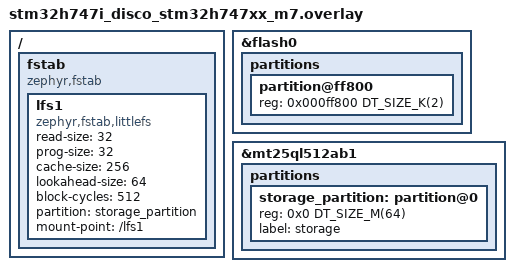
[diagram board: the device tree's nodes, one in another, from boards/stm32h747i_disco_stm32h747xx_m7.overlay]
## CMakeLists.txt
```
# SPDX-License-Identifier: Apache-2.0

cmake_minimum_required(VERSION 3.28.0)
find_package(Zephyr REQUIRED HINTS $ENV{ZEPHYR_BASE})
project(lvgl)

FILE(GLOB app_sources src/*.c)
target_sources(app PRIVATE ${app_sources})
```

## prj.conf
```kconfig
CONFIG_ZTEST=y

CONFIG_DISPLAY=y
CONFIG_SDL_DISPLAY=n

CONFIG_LOG=y

CONFIG_FLASH=y
CONFIG_FLASH_MAP=y
CONFIG_FILE_SYSTEM=y
CONFIG_FILE_SYSTEM_LITTLEFS=y
CONFIG_LV_Z_AUTO_INIT=n

CONFIG_LVGL=y
CONFIG_LV_Z_MEM_POOL_SIZE=16384
CONFIG_LV_Z_USE_FILESYSTEM=y
CONFIG_LV_USE_LOG=y
CONFIG_LV_Z_COLOR_FORMAT_XRGB8888=y
CONFIG_LV_USE_BIDI=y
CONFIG_LV_USE_ARABIC_PERSIAN_CHARS=y
CONFIG_LV_USE_LABEL=y
CONFIG_LV_LABEL_TEXT_SELECTION=y
CONFIG_LV_LABEL_LONG_TXT_HINT=y
CONFIG_LV_USE_LINE=y
CONFIG_LV_USE_ARC=y
CONFIG_LV_USE_WIN=y
CONFIG_LV_USE_TABVIEW=y
CONFIG_LV_USE_TILEVIEW=y
CONFIG_LV_USE_CALENDAR=y
CONFIG_LV_CALENDAR_WEEK_STARTS_MONDAY=y
CONFIG_LV_USE_SPINNER=y
CONFIG_LV_USE_CANVAS=y
CONFIG_LV_USE_BAR=y
CONFIG_LV_USE_CHART=y
CONFIG_LV_USE_TABLE=y
CONFIG_LV_USE_LED=y
CONFIG_LV_USE_MSGBOX=y
CONFIG_LV_USE_TEXTAREA=y
CONFIG_LV_USE_SPINBOX=y
CONFIG_LV_USE_KEYBOARD=y
CONFIG_LV_USE_CHECKBOX=y
CONFIG_LV_USE_LIST=y
CONFIG_LV_USE_DROPDOWN=y
CONFIG_LV_USE_ROLLER=y
CONFIG_LV_USE_SLIDER=y
CONFIG_LV_USE_SWITCH=y
CONFIG_LV_USE_LED=y
CONFIG_LV_FONT_MONTSERRAT_8=y
CONFIG_LV_FONT_MONTSERRAT_10=y
CONFIG_LV_FONT_MONTSERRAT_12=y
CONFIG_LV_FONT_MONTSERRAT_14=y
CONFIG_LV_FONT_MONTSERRAT_16=y
CONFIG_LV_FONT_MONTSERRAT_18=y
CONFIG_LV_FONT_MONTSERRAT_20=y
CONFIG_LV_FONT_MONTSERRAT_22=y
CONFIG_LV_FONT_MONTSERRAT_24=y
CONFIG_LV_FONT_MONTSERRAT_26=y
CONFIG_LV_FONT_MONTSERRAT_28=y
CONFIG_LV_FONT_MONTSERRAT_30=y
CONFIG_LV_FONT_MONTSERRAT_32=y
CONFIG_LV_FONT_MONTSERRAT_34=y
CONFIG_LV_FONT_MONTSERRAT_36=y
CONFIG_LV_FONT_MONTSERRAT_38=y
CONFIG_LV_FONT_MONTSERRAT_40=y
CONFIG_LV_FONT_MONTSERRAT_42=y
CONFIG_LV_FONT_MONTSERRAT_44=y
CONFIG_LV_FONT_MONTSERRAT_46=y
CONFIG_LV_FONT_MONTSERRAT_48=y
CONFIG_LV_FONT_MONTSERRAT_28_COMPRESSED=y
CONFIG_LV_FONT_DEJAVU_16_PERSIAN_HEBREW=y
CONFIG_LV_FONT_SOURCE_HAN_SANS_SC_16_CJK=y
CONFIG_LV_FONT_UNSCII_8=y
CONFIG_LV_USE_FONT_COMPRESSED=y
```

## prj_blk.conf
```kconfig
CONFIG_DISK_DRIVERS=y
CONFIG_DISK_ACCESS=y

CONFIG_FS_LITTLEFS_BLK_DEV=y

CONFIG_FS_LITTLEFS_FC_HEAP_SIZE=2048
CONFIG_MAIN_STACK_SIZE=2048

CONFIG_FLASH=n
CONFIG_FLASH_MAP=n
```

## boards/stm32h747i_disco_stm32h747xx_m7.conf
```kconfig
# SPDX-FileCopyrightText: Copyright The Zephyr Project Contributors
# SPDX-License-Identifier: Apache-2.0

CONFIG_FS_LITTLEFS_FC_HEAP_SIZE=2048
CONFIG_MAIN_STACK_SIZE=2048

CONFIG_DUMMY_DISPLAY=n

CONFIG_NOCACHE_MEMORY=y
```

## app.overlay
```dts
/*
 * Copyright (c) 2021 Nordic Semiconductor ASA
 *
 * SPDX-License-Identifier: Apache-2.0
 */

/ {
	chosen {
		zephyr,display = &dummy_dc;
	};

	dummy_dc: dummy_dc {
		compatible = "zephyr,dummy-dc";
		height = <240>;
		width = <320>;
	};
};
```

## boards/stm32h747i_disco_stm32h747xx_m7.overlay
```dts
/*
 * Copyright (c) 2024 STMicroelectronics
 *
 * SPDX-License-Identifier: Apache-2.0
 */

/delete-node/ &storage_partition;

&flash0 {
	partitions {
		partition@ff800 {
			reg = <0x000ff800 DT_SIZE_K(2)>;
		};
	};
};

/ {
	fstab {
		compatible = "zephyr,fstab";

		lfs1: lfs1 {
			compatible = "zephyr,fstab,littlefs";
			read-size = <32>;
			prog-size = <32>;
			cache-size = <256>;
			lookahead-size = <64>;
			block-cycles = <512>;
			partition = <&storage_partition>;
			mount-point = "/lfs1";
		};
	};
};

&mt25ql512ab1 {
	partitions {
		storage_partition: partition@0 {
			reg = <0x0 DT_SIZE_M(64)>;
			label = "storage";
		};
	};
};
```

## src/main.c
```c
/*
 * Copyright (c) 2019 Jan Van Winkel <jan.van_winkel@dxplore.eu>
 * Copyright (c) 2024 STMicroelectronics
 *
 * SPDX-License-Identifier: Apache-2.0
 */

#include "img.h"

#include <zephyr/kernel.h>
#include <zephyr/device.h>
#include <zephyr/drivers/display.h>
#include <zephyr/fs/fs.h>
#include <zephyr/fs/littlefs.h>
#include <zephyr/ztest.h>
#include <lvgl_zephyr.h>

#include <lvgl.h>

#ifdef CONFIG_FS_LITTLEFS_BLK_DEV

#ifdef CONFIG_DISK_DRIVER_SDMMC
#define DISK_NAME "SD"
#elif defined(CONFIG_DISK_DRIVER_MMC)
#define DISK_NAME "SD2"
#else
#error "No disk device defined, is your board supported?"
#endif /* CONFIG_DISK_DRIVER_SDMMC */

#define IMG_FILE_PATH "/"DISK_NAME":/img.bin"

struct fs_littlefs lfsfs;

static struct fs_mount_t mnt = {
	.type = FS_LITTLEFS,
	.fs_data = &lfsfs,
	.storage_dev = (void *)DISK_NAME,
	.mnt_point = "/"DISK_NAME":",
	.flags = FS_MOUNT_FLAG_USE_DISK_ACCESS,
};

#else /* CONFIG_FS_LITTLEFS_BLK_DEV */

#define IMG_FILE_PATH "/mnt/img.bin"

#define LVGL_PARTITION		storage_partition
#define LVGL_PARTITION_ID	PARTITION_ID(LVGL_PARTITION)

FS_LITTLEFS_DECLARE_DEFAULT_CONFIG(cstorage);

static struct fs_mount_t mnt = {
	.type = FS_LITTLEFS,
	.fs_data = &cstorage,
	.storage_dev = (void *)LVGL_PARTITION_ID,
	.mnt_point = "/mnt"
};
#endif /* CONFIG_FS_LITTLEFS_BLK_DEV */

static const struct device *display_dev = DEVICE_DT_GET(DT_CHOSEN(zephyr_display));

ZTEST(lvgl_screen, test_get_default_screen)
{
	zassert_not_null(lv_scr_act(), "No default screen");
}

ZTEST(lvgl_screen, test_add_delete_screen)
{
	lv_obj_t *default_screen = lv_scr_act();

	zassert_not_null(default_screen, "No default screen");

	lv_obj_t *new_screen = lv_obj_create(NULL);

	zassert_not_null(new_screen, "Failed to create new screen");

	lv_scr_load(new_screen);

	lv_obj_t *act_screen = lv_scr_act();

	zassert_equal_ptr(act_screen, new_screen, "New screen not active");

	lv_scr_load(default_screen);

	lv_obj_del(new_screen);

	act_screen = lv_scr_act();
	zassert_equal_ptr(act_screen, default_screen,
			"Default screen not active");

}
ZTEST_USER(lvgl_fs, test_add_img)
{
	lv_obj_t *img = lv_img_create(lv_scr_act());

	zassert_not_null(img, "Failed to create image");

	lv_img_set_src(img, IMG_FILE_PATH);
	lv_obj_align(img, LV_ALIGN_CENTER, 0, 0);
}

void *setup_lvgl(void)
{
	int ret;

#if defined(CONFIG_LV_COLOR_FORMAT_I1)
	display_set_pixel_format(display_dev, PIXEL_FORMAT_MONO10);
#elif defined(CONFIG_LV_COLOR_FORMAT_L8)
	display_set_pixel_format(display_dev, PIXEL_FORMAT_L_8);
#elif defined(CONFIG_LV_COLOR_FORMAT_RGB888)
	display_set_pixel_format(display_dev, PIXEL_FORMAT_RGB_888);
#elif defined(CONFIG_LV_COLOR_FORMAT_RGB565)
	display_set_pixel_format(display_dev, PIXEL_FORMAT_RGB_565);
#elif defined(CONFIG_LV_COLOR_FORMAT_XRGB8888)
	display_set_pixel_format(display_dev, PIXEL_FORMAT_ARGB_8888);
#else
#error "No display pixel format defined, is your board supported?"
#endif

	ret = lvgl_init();
	zassert_equal(ret, 0, "Failed to initialize lvgl");

	return NULL;
}

void *setup_fs(void)
{
	struct fs_file_t img;
	struct fs_dirent info;
	int ret;
	const lv_image_dsc_t *c_img = get_lvgl_img();

	setup_lvgl();

	ret = fs_mount(&mnt);
	if (ret < 0) {
		TC_PRINT("Failed to mount file system: %d\n", ret);
		ztest_test_fail();
		return NULL;
	}

	ret = fs_stat(IMG_FILE_PATH, &info);
	if ((ret == 0) && (info.type == FS_DIR_ENTRY_FILE)) {
		return NULL;
	}

	fs_file_t_init(&img);
	ret = fs_open(&img, IMG_FILE_PATH, FS_O_CREATE | FS_O_WRITE);
	if (ret < 0) {
		TC_PRINT("Failed to open image file: %d\n", ret);
		ztest_test_fail();
		return NULL;
	}

	ret = fs_write(&img, &c_img->header, sizeof(lv_image_header_t));
	if (ret < 0) {
		TC_PRINT("Failed to write image file header: %d\n", ret);
		ztest_test_fail();
		return NULL;
	}

	ret = fs_write(&img, c_img->data, c_img->data_size);
	if (ret < 0) {
		TC_PRINT("Failed to write image file data: %d\n", ret);
		ztest_test_fail();
		return NULL;
	}

	ret = fs_close(&img);
	if (ret < 0) {
		TC_PRINT("Failed to close image file: %d\n", ret);
		ztest_test_fail();
		return NULL;
	}
	return NULL;
}

void teardown_lvgl(void *data)
{
	lv_deinit();
}

ZTEST(lvgl_mono, test_mono_display)
{
	int ret;

	zassert_ok(display_set_pixel_format(display_dev, PIXEL_FORMAT_MONO10));
	ret = lvgl_init();
	zassert_ok(display_set_pixel_format(display_dev, PIXEL_FORMAT_ARGB_8888));

	if (!IS_ENABLED(CONFIG_LV_COLOR_FORMAT_I1)) {
		zassert_equal(ret, -ENOTSUP, "MONO10 accepted without CONFIG_LV_COLOR_FORMAT_I1");
		return;
	}

	zassert_ok(ret, "MONO10 rejected with CONFIG_LV_COLOR_FORMAT_I1");
	lv_label_set_text(lv_label_create(lv_screen_active()), "mono");
	lv_refr_now(NULL);
}

ZTEST_SUITE(lvgl_screen, NULL, setup_lvgl, NULL, NULL, teardown_lvgl);
ZTEST_SUITE(lvgl_fs, NULL, setup_fs, NULL, NULL, teardown_lvgl);
ZTEST_SUITE(lvgl_mono, NULL, NULL, NULL, NULL, teardown_lvgl);
```

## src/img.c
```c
/*
 * Copyright (c) 2019 Jan Van Winkel <jan.van_winkel@dxplore.eu>
 *
 * SPDX-License-Identifier: Apache-2.0
 */

#include <zephyr/kernel.h>
#include "img.h"

static const uint8_t img_data[] = {
	0x00, 0x00, 0x00, 0x00,	/* Index color 0 */
	0x00, 0xff, 0x00, 0x00,	/* Index color 1 */

/* 0 */
	0xff, 0xff, 0xff, 0xff, 0xff, 0xff, 0xff, 0xff, 0xff, 0xff, 0xff, 0xff,
	0xff, 0xff, 0xff, 0xff, 0xff, 0xff, 0xff, 0xff, 0xff, 0xff, 0xff, 0xff,
	0xff, 0xff, 0xff, 0xff, 0xff, 0xff, 0xff, 0xff, 0xff, 0xff, 0xff, 0xff,
	0xff, 0xff, 0xff, 0xff, 0xff, 0xff, 0xff, 0xff, 0xff, 0xff, 0xff, 0xff,
	0xff, 0xff, 0xff, 0xff, 0xff, 0xff, 0xff, 0xff, 0xff, 0xff, 0xff, 0xff,
	0xff, 0x00, 0x00, 0x00, 0x00, 0x00, 0x00, 0x00, 0x00, 0x00, 0x00, 0xff,
	0xff, 0x00, 0x00, 0x00, 0x00, 0x00, 0x00, 0x00, 0x00, 0x00, 0x00, 0xff,
	0xff, 0x00, 0x00, 0x00, 0x00, 0x00, 0x00, 0x00, 0x00, 0x00, 0x00, 0xff,
	0xff, 0x00, 0x00, 0x00, 0x00, 0x00, 0x00, 0x00, 0x00, 0x00, 0x00, 0xff,
	0xff, 0x00, 0x00, 0x00, 0x00, 0x00, 0x00, 0x00, 0x00, 0x00, 0x00, 0xff,
/* 10 */
	0xff, 0xff, 0xff, 0xff, 0xff, 0xff, 0xff, 0xff, 0xff, 0xff, 0xff, 0xff,
	0xff, 0xff, 0xff, 0xff, 0xff, 0xff, 0xff, 0xff, 0xff, 0xff, 0xff, 0xff,
	0xff, 0xff, 0xff, 0xff, 0xff, 0xff, 0xff, 0xff, 0xff, 0xff, 0xff, 0xff,
	0xff, 0xff, 0xff, 0xff, 0xff, 0xff, 0xff, 0xff, 0xff, 0xff, 0xff, 0xff,
	0xff, 0xff, 0xff, 0xff, 0xff, 0xff, 0xff, 0xff, 0xff, 0xff, 0xff, 0xff,
	0xff, 0x00, 0x00, 0x00, 0x00, 0x00, 0x00, 0x00, 0x00, 0x00, 0x00, 0xff,
	0xff, 0x00, 0x00, 0x00, 0x00, 0x00, 0x00, 0x00, 0x00, 0x00, 0x00, 0xff,
	0xff, 0x00, 0x00, 0x00, 0x00, 0x00, 0x00, 0x00, 0x00, 0x00, 0x00, 0xff,
	0xff, 0x00, 0x00, 0x00, 0x00, 0x00, 0x00, 0x00, 0x00, 0x00, 0x00, 0xff,
	0xff, 0x00, 0x00, 0x00, 0x00, 0x00, 0x00, 0x00, 0x00, 0x00, 0x00, 0xff,
/* 20 */
	0xff, 0xff, 0xff, 0xff, 0xff, 0xff, 0xff, 0xff, 0xff, 0xff, 0xff, 0xff,
	0xff, 0xff, 0xff, 0xff, 0xff, 0xff, 0xff, 0xff, 0xff, 0xff, 0xff, 0xff,
	0xff, 0xff, 0xff, 0xff, 0xff, 0xff, 0xff, 0xff, 0xff, 0xff, 0xff, 0xff,
	0xff, 0xff, 0xff, 0xff, 0xff, 0xff, 0xff, 0xff, 0xff, 0xff, 0xff, 0xff,
	0xff, 0xff, 0xff, 0xff, 0xff, 0xff, 0xff, 0xff, 0xff, 0xff, 0xff, 0xff,
	0xff, 0x00, 0x00, 0x00, 0x00, 0x00, 0x00, 0x00, 0x00, 0x00, 0x00, 0xff,
	0xff, 0x00, 0x00, 0x00, 0x00, 0x00, 0x00, 0x00, 0x00, 0x00, 0x00, 0xff,
	0xff, 0x00, 0x00, 0x00, 0x00, 0x00, 0x00, 0x00, 0x00, 0x00, 0x00, 0xff,
	0xff, 0x00, 0x00, 0x00, 0x00, 0x00, 0x00, 0x00, 0x00, 0x00, 0x00, 0xff,
	0xff, 0x00, 0x00, 0x00, 0x00, 0x00, 0x00, 0x00, 0x00, 0x00, 0x00, 0xff,
/* 30 */
	0xff, 0xff, 0xff, 0xff, 0xff, 0xff, 0xff, 0xff, 0xff, 0xff, 0xff, 0xff,
	0xff, 0xff, 0xff, 0xff, 0xff, 0xff, 0xff, 0xff, 0xff, 0xff, 0xff, 0xff,
	0xff, 0xff, 0xff, 0xff, 0xff, 0xff, 0xff, 0xff, 0xff, 0xff, 0xff, 0xff,
	0xff, 0xff, 0xff, 0xff, 0xff, 0xff, 0xff, 0xff, 0xff, 0xff, 0xff, 0xff,
	0xff, 0xff, 0xff, 0xff, 0xff, 0xff, 0xff, 0xff, 0xff, 0xff, 0xff, 0xff,
	0xff, 0x00, 0x00, 0x00, 0x00, 0x00, 0x00, 0x00, 0x00, 0x00, 0x00, 0xff,
	0xff, 0x00, 0x00, 0x00, 0x00, 0x00, 0x00, 0x00, 0x00, 0x00, 0x00, 0xff,
	0xff, 0x00, 0x00, 0x00, 0x00, 0x00, 0x00, 0x00, 0x00, 0x00, 0x00, 0xff,
	0xff, 0x00, 0x00, 0x00, 0x00, 0x00, 0x00, 0x00, 0x00, 0x00, 0x00, 0xff,
	0xff, 0x00, 0x00, 0x00, 0x00, 0x00, 0x00, 0x00, 0x00, 0x00, 0x00, 0xff,
/* 40 */
	0xff, 0xff, 0xff, 0xff, 0xff, 0xff, 0xff, 0xff, 0xff, 0xff, 0xff, 0xff,
	0xff, 0xff, 0xff, 0xff, 0xff, 0xff, 0xff, 0xff, 0xff, 0xff, 0xff, 0xff,
	0xff, 0xff, 0xff, 0xff, 0xff, 0xff, 0xff, 0xff, 0xff, 0xff, 0xff, 0xff,
	0xff, 0xff, 0xff, 0xff, 0xff, 0xff, 0xff, 0xff, 0xff, 0xff, 0xff, 0xff,
	0xff, 0xff, 0xff, 0xff, 0xff, 0xff, 0xff, 0xff, 0xff, 0xff, 0xff, 0xff,
	0xff, 0x00, 0x00, 0x00, 0x00, 0x00, 0x00, 0x00, 0x00, 0x00, 0x00, 0xff,
	0xff, 0x00, 0x00, 0x00, 0x00, 0x00, 0x00, 0x00, 0x00, 0x00, 0x00, 0xff,
	0xff, 0x00, 0x00, 0x00, 0x00, 0x00, 0x00, 0x00, 0x00, 0x00, 0x00, 0xff,
	0xff, 0x00, 0x00, 0x00, 0x00, 0x00, 0x00, 0x00, 0x00, 0x00, 0x00, 0xff,
	0xff, 0x00, 0x00, 0x00, 0x00, 0x00, 0x00, 0x00, 0x00, 0x00, 0x00, 0xff,
/* 50 */
	0xff, 0xff, 0xff, 0xff, 0xff, 0xff, 0xff, 0xff, 0xff, 0xff, 0xff, 0xff,
	0xff, 0xff, 0xff, 0xff, 0xff, 0xff, 0xff, 0xff, 0xff, 0xff, 0xff, 0xff,
	0xff, 0xff, 0xff, 0xff, 0xff, 0xff, 0xff, 0xff, 0xff, 0xff, 0xff, 0xff,
	0xff, 0xff, 0xff, 0xff, 0xff, 0xff, 0xff, 0xff, 0xff, 0xff, 0xff, 0xff,
	0xff, 0xff, 0xff, 0xff, 0xff, 0xff, 0xff, 0xff, 0xff, 0xff, 0xff, 0xff,
	0xff, 0x00, 0x00, 0x00, 0x00, 0x00, 0x00, 0x00, 0x00, 0x00, 0x00, 0xff,
	0xff, 0x00, 0x00, 0x00, 0x00, 0x00, 0x00, 0x00, 0x00, 0x00, 0x00, 0xff,
	0xff, 0x00, 0x00, 0x00, 0x00, 0x00, 0x00, 0x00, 0x00, 0x00, 0x00, 0xff,
	0xff, 0x00, 0x00, 0x00, 0x00, 0x00, 0x00, 0x00, 0x00, 0x00, 0x00, 0xff,
	0xff, 0x00, 0x00, 0x00, 0x00, 0x00, 0x00, 0x00, 0x00, 0x00, 0x00, 0xff,
/* 60 */
	0xff, 0xff, 0xff, 0xff, 0xff, 0xff, 0xff, 0xff, 0xff, 0xff, 0xff, 0xff,
	0xff, 0xff, 0xff, 0xff, 0xff, 0xff, 0xff, 0xff, 0xff, 0xff, 0xff, 0xff,
	0xff, 0xff, 0xff, 0xff, 0xff, 0xff, 0xff, 0xff, 0xff, 0xff, 0xff, 0xff,
	0xff, 0xff, 0xff, 0xff, 0xff, 0xff, 0xff, 0xff, 0xff, 0xff, 0xff, 0xff,
	0xff, 0xff, 0xff, 0xff, 0xff, 0xff, 0xff, 0xff, 0xff, 0xff, 0xff, 0xff,
	0xff, 0x00, 0x00, 0x00, 0x00, 0x00, 0x00, 0x00, 0x00, 0x00, 0x00, 0xff,
	0xff, 0x00, 0x00, 0x00, 0x00, 0x00, 0x00, 0x00, 0x00, 0x00, 0x00, 0xff,
	0xff, 0x00, 0x00, 0x00, 0x00, 0x00, 0x00, 0x00, 0x00, 0x00, 0x00, 0xff,
	0xff, 0x00, 0x00, 0x00, 0x00, 0x00, 0x00, 0x00, 0x00, 0x00, 0x00, 0xff,
	0xff, 0x00, 0x00, 0x00, 0x00, 0x00, 0x00, 0x00, 0x00, 0x00, 0x00, 0xff,
/* 70 */
	0xff, 0xff, 0xff, 0xff, 0xff, 0xff, 0xff, 0xff, 0xff, 0xff, 0xff, 0xff,
	0xff, 0xff, 0xff, 0xff, 0xff, 0xff, 0xff, 0xff, 0xff, 0xff, 0xff, 0xff,
	0xff, 0xff, 0xff, 0xff, 0xff, 0xff, 0xff, 0xff, 0xff, 0xff, 0xff, 0xff,
	0xff, 0xff, 0xff, 0xff, 0xff, 0xff, 0xff, 0xff, 0xff, 0xff, 0xff, 0xff,
	0xff, 0xff, 0xff, 0xff, 0xff, 0xff, 0xff, 0xff, 0xff, 0xff, 0xff, 0xff,
	0xff, 0x00, 0x00, 0x00, 0x00, 0x00, 0x00, 0x00, 0x00, 0x00, 0x00, 0xff,
	0xff, 0x00, 0x00, 0x00, 0x00, 0x00, 0x00, 0x00, 0x00, 0x00, 0x00, 0xff,
	0xff, 0x00, 0x00, 0x00, 0x00, 0x00, 0x00, 0x00, 0x00, 0x00, 0x00, 0xff,
	0xff, 0x00, 0x00, 0x00, 0x00, 0x00, 0x00, 0x00, 0x00, 0x00, 0x00, 0xff,
	0xff, 0x00, 0x00, 0x00, 0x00, 0x00, 0x00, 0x00, 0x00, 0x00, 0x00, 0xff,
/* 80 */
	0xff, 0xff, 0xff, 0xff, 0xff, 0xff, 0xff, 0xff, 0xff, 0xff, 0xff, 0xff,
	0xff, 0xff, 0xff, 0xff, 0xff, 0xff, 0xff, 0xff, 0xff, 0xff, 0xff, 0xff,
	0xff, 0xff, 0xff, 0xff, 0xff, 0xff, 0xff, 0xff, 0xff, 0xff, 0xff, 0xff,
	0xff, 0xff, 0xff, 0xff, 0xff, 0xff, 0xff, 0xff, 0xff, 0xff, 0xff, 0xff,
	0xff, 0xff, 0xff, 0xff, 0xff, 0xff, 0xff, 0xff, 0xff, 0xff, 0xff, 0xff,
	0xff, 0x00, 0x00, 0x00, 0x00, 0x00, 0x00, 0x00, 0x00, 0x00, 0x00, 0xff,
	0xff, 0x00, 0x00, 0x00, 0x00, 0x00, 0x00, 0x00, 0x00, 0x00, 0x00, 0xff,
	0xff, 0x00, 0x00, 0x00, 0x00, 0x00, 0x00, 0x00, 0x00, 0x00, 0x00, 0xff,
	0xff, 0x00, 0x00, 0x00, 0x00, 0x00, 0x00, 0x00, 0x00, 0x00, 0x00, 0xff,
	0xff, 0x00, 0x00, 0x00, 0x00, 0x00, 0x00, 0x00, 0x00, 0x00, 0x00, 0xff,
/* 90 */
	0xff, 0xff, 0xff, 0xff, 0xff, 0xff, 0xff, 0xff, 0xff, 0xff, 0xff, 0xff,
	0xff, 0xff, 0xff, 0xff, 0xff, 0xff, 0xff, 0xff, 0xff, 0xff, 0xff, 0xff,
	0xff, 0xff, 0xff, 0xff, 0xff, 0xff, 0xff, 0xff, 0xff, 0xff, 0xff, 0xff,
	0xff, 0xff, 0xff, 0xff, 0xff, 0xff, 0xff, 0xff, 0xff, 0xff, 0xff, 0xff,
	0xff, 0xff, 0xff, 0xff, 0xff, 0xff, 0xff, 0xff, 0xff, 0xff, 0xff, 0xff,
	0xff, 0xff, 0xff, 0xff, 0xff, 0xff, 0xff, 0xff, 0xff, 0xff, 0xff, 0xff,
/* 96 */
};

static lv_image_dsc_t img_dsc = {
	.header.w = 96,
	.header.h = 96,
	.data_size = sizeof(img_data),
	.header.cf = LV_COLOR_FORMAT_I1,
	.data = img_data,
};


const lv_image_dsc_t *get_lvgl_img(void)
{
	return &img_dsc;
}
```

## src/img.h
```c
/*
 * Copyright (c) 2019 Jan Van Winkel <jan.van_winkel@dxplore.eu>
 *
 * SPDX-License-Identifier: Apache-2.0
 */

#ifndef ZEPHYR_TEST_LIB_GUI_LVGL_IMG_H_
#define ZEPHYR_TEST_LIB_GUI_LVGL_IMG_H_

#include <lvgl.h>


const lv_img_dsc_t *get_lvgl_img(void);

#endif /* ZEPHYR_TEST_LIB_GUI_LVGL_IMG_H_ */
```
